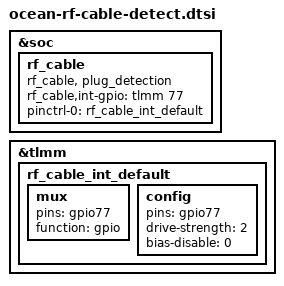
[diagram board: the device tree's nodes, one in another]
&soc {
       rf_cable {
               compatible = "rf_cable, plug_detection";
               rf_cable,int-gpio = <&tlmm 77 0>;
               pinctrl-names = "default";
               pinctrl-0 = <&rf_cable_int_default>;
       };
};

&tlmm {
	rf_cable_int_default: rf_cable_int_default {
		mux {
			pins = "gpio77";
			function = "gpio";
		};
		config {
			pins = "gpio77";
			drive-strength = <2>;
			bias-disable = <0>; /* no pull */
		};
	 };
};
